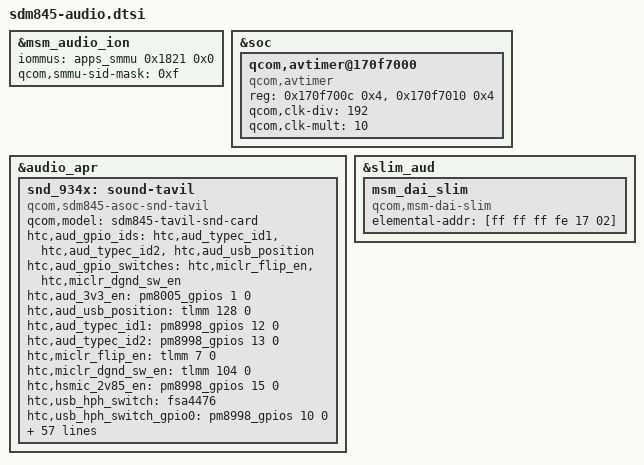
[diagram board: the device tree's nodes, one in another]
/*
 * Copyright (c) 2016-2018, The Linux Foundation. All rights reserved.
 *
 * This program is free software; you can redistribute it and/or modify
 * it under the terms of the GNU General Public License version 2 and
 * only version 2 as published by the Free Software Foundation.
 *
 * This program is distributed in the hope that it will be useful,
 * but WITHOUT ANY WARRANTY; without even the implied warranty of
 * MERCHANTABILITY or FITNESS FOR A PARTICULAR PURPOSE.  See the
 * GNU General Public License for more details.
 */

#include "msm-audio-lpass.dtsi"

&msm_audio_ion {
	iommus = <&apps_smmu 0x1821 0x0>;
	qcom,smmu-sid-mask = /bits/ 64 <0xf>;
};

&soc {
	qcom,avtimer@170f7000 {
		compatible = "qcom,avtimer";
		reg = <0x170f700c 0x4>,
		      <0x170f7010 0x4>;
		reg-names = "avtimer_lsb_addr", "avtimer_msb_addr";
		qcom,clk-div = <192>;
		qcom,clk-mult = <10>;
	};
};

&audio_apr {
	snd_934x: sound-tavil {
		compatible = "qcom,sdm845-asoc-snd-tavil";
		qcom,model = "sdm845-tavil-snd-card";
		/* htc typec headset detection */
		htc,aud_gpio_ids = "htc,aud_typec_id1",
				"htc,aud_typec_id2",
				"htc,aud_usb_position";

		htc,aud_gpio_switches = "htc,miclr_flip_en",
				"htc,miclr_dgnd_sw_en";

		htc,aud_3v3_en = <&pm8005_gpios 1 0>;
		htc,aud_usb_position = <&tlmm 128 0>;
		htc,aud_typec_id1 = <&pm8998_gpios 12 0>;
		htc,aud_typec_id2 = <&pm8998_gpios 13 0>;
		htc,miclr_flip_en = <&tlmm 7 0>;
		htc,miclr_dgnd_sw_en = <&tlmm 104 0>;
		htc,hsmic_2v85_en = <&pm8998_gpios 15 0>;

/*
		htc,aud_remote_sensor = <&pm8998_gpios 9 0>;
		htc,adapter_35mm_threshold = <330 800>;
		htc,adapter_25mm_threshold = <1250 2850>;

		htc,headset_adc_channel = <19>;
		qcom,headset-vadc = <&pm8998_vadc>;
		htc,mbhc_hsdet_l = <&tlmm 79 0>;
*/
		htc,usb_hph_switch = "fsa4476";
		htc,usb_hph_switch_gpio0 = <&pm8998_gpios 10 0>; /* FSA4476 ENN */
		htc,usb_hph_switch_gpio1 = <&pm8998_gpios 6 0>; /* FSA4476 EN1 */
		htc,usb_hph_switch_gpio2 = <&pm8998_gpios 7 0>; /* FSA4476 EN2 */

		htc,mbhc-swap-detect = <0>; /* Disable MBHC SWAP detection */
		qcom,ext-disp-audio-rx;
		qcom,wcn-btfm;
		qcom,mi2s-audio-intf;
		qcom,auxpcm-audio-intf;
		qcom,msm-mi2s-master = <1>, <1>, <1>, <1>;

		asoc-platform = <&pcm0>, <&pcm1>, <&pcm2>, <&voip>, <&voice>,
				<&loopback>, <&compress>, <&hostless>,
				<&afe>, <&lsm>, <&routing>, <&compr>,
				<&pcm_noirq>;
		asoc-platform-names = "msm-pcm-dsp.0", "msm-pcm-dsp.1",
				"msm-pcm-dsp.2", "msm-voip-dsp",
				"msm-pcm-voice", "msm-pcm-loopback",
				"msm-compress-dsp", "msm-pcm-hostless",
				"msm-pcm-afe", "msm-lsm-client",
				"msm-pcm-routing", "msm-compr-dsp",
				"msm-pcm-dsp-noirq";
		asoc-cpu = <&dai_hdmi>, <&dai_dp>,
				<&dai_mi2s0>, <&dai_mi2s1>,
				<&dai_mi2s2>, <&dai_mi2s3>,
				<&dai_pri_auxpcm>, <&dai_sec_auxpcm>,
				<&dai_tert_auxpcm>, <&dai_quat_auxpcm>,
				<&sb_0_rx>, <&sb_0_tx>, <&sb_1_rx>, <&sb_1_tx>,
				<&sb_2_rx>, <&sb_2_tx>, <&sb_3_rx>, <&sb_3_tx>,
				<&sb_4_rx>, <&sb_4_tx>, <&sb_5_tx>,
				<&afe_pcm_rx>, <&afe_pcm_tx>, <&afe_proxy_rx>,
				<&afe_proxy_tx>, <&incall_record_rx>,
				<&incall_record_tx>, <&incall_music_rx>,
				<&incall_music_2_rx>, <&sb_5_rx>, <&sb_6_rx>,
				<&sb_7_rx>, <&sb_7_tx>, <&sb_8_tx>,
				<&usb_audio_rx>, <&usb_audio_tx>,
				<&dai_pri_tdm_rx_0>, <&dai_pri_tdm_tx_0>,
				<&dai_sec_tdm_rx_0>, <&dai_sec_tdm_tx_0>,
				<&dai_tert_tdm_rx_0>, <&dai_tert_tdm_tx_0>,
				<&dai_quat_tdm_rx_0>, <&dai_quat_tdm_tx_0>;
		asoc-cpu-names = "msm-dai-q6-hdmi.8",  "msm-dai-q6-dp.24608",
				"msm-dai-q6-mi2s.0", "msm-dai-q6-mi2s.1",
				"msm-dai-q6-mi2s.2", "msm-dai-q6-mi2s.3",
				"msm-dai-q6-auxpcm.1", "msm-dai-q6-auxpcm.2",
				"msm-dai-q6-auxpcm.3", "msm-dai-q6-auxpcm.4",
				"msm-dai-q6-dev.16384", "msm-dai-q6-dev.16385",
				"msm-dai-q6-dev.16386", "msm-dai-q6-dev.16387",
				"msm-dai-q6-dev.16388", "msm-dai-q6-dev.16389",
				"msm-dai-q6-dev.16390", "msm-dai-q6-dev.16391",
				"msm-dai-q6-dev.16392", "msm-dai-q6-dev.16393",
				"msm-dai-q6-dev.16395", "msm-dai-q6-dev.224",
				"msm-dai-q6-dev.225", "msm-dai-q6-dev.241",
				"msm-dai-q6-dev.240", "msm-dai-q6-dev.32771",
				"msm-dai-q6-dev.32772", "msm-dai-q6-dev.32773",
				"msm-dai-q6-dev.32770", "msm-dai-q6-dev.16394",
				"msm-dai-q6-dev.16396", "msm-dai-q6-dev.16398",
				"msm-dai-q6-dev.16399", "msm-dai-q6-dev.16401",
				"msm-dai-q6-dev.28672", "msm-dai-q6-dev.28673",
				"msm-dai-q6-tdm.36864", "msm-dai-q6-tdm.36865",
				"msm-dai-q6-tdm.36880", "msm-dai-q6-tdm.36881",
				"msm-dai-q6-tdm.36896", "msm-dai-q6-tdm.36897",
				"msm-dai-q6-tdm.36912", "msm-dai-q6-tdm.36913";
	};
};

&slim_aud {
	msm_dai_slim {
		compatible = "qcom,msm-dai-slim";
		elemental-addr = [ff ff ff fe 17 02];
	};
};
